# ATSAMR21E/GA register map
Vendor: Atmel Corporation; Series: SAMR21; File version: A
CPU: CM0+ r0p1, little endian, no MPU, no FPU, VTOR, 2 interrupt priority bits
Registers are 8-bit, read-write, reset 0x0 unless marked. A register's access mark holds for its fields unless they carry their own. Offsets are from the block's base; [hi:lo] are bit positions; {n}, {i} and the like mark numbered series; 'fields as' and 'values as' point back to an identical list.

## TCC0 — Timer Counter Control 0
Base 0x42002000; register names take the prefix TCC_
Same registers: TCC1 0x42002400, TCC2 0x42002800
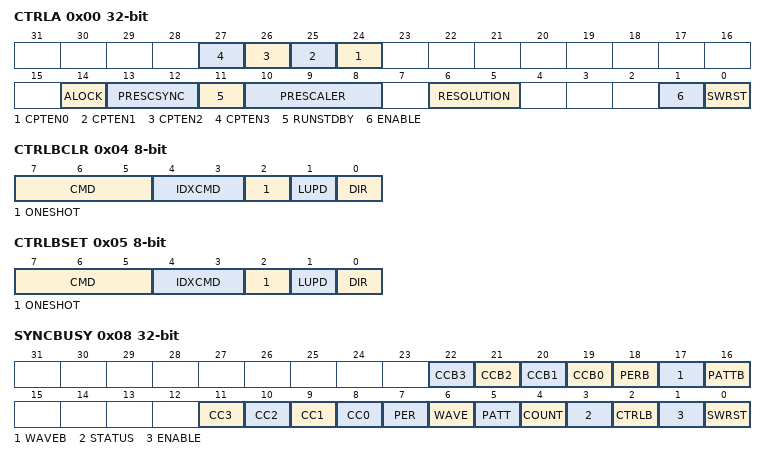
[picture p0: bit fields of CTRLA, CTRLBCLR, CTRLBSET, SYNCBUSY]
0x00 CTRLA 32-bit — Control A
  [n+24] CPTEN{n} (n=0..3) — Capture Channel {n} Enable
  [14] ALOCK — Auto Lock
  [13:12] PRESCSYNC — Prescaler and Counter Synchronization Selection
    0=GCLK (Reload or reset Counter on next GCLK); 1=PRESC (Reload or reset Counter on next prescaler clock); 2=RESYNC (Reload or reset Counter on next GCLK)
  [11] RUNSTDBY — Run in Standby
  [10:8] PRESCALER
    0=DIV1 (Prescaler: GCLK_TCC); 1=DIV2 (Prescaler: GCLK_TCC/2); 2=DIV4 (Prescaler: GCLK_TCC/4); 3=DIV8 (Prescaler: GCLK_TCC/8); 4=DIV16 (Prescaler: GCLK_TCC/16); 5=DIV64 (Prescaler: GCLK_TCC/64); 6=DIV256 (Prescaler: GCLK_TCC/256); 7=DIV1024 (Prescaler: GCLK_TCC/1024)
  [6:5] RESOLUTION — Enhanced Resolution
    0=None (Dithering is disabled); 1=DITH4 (Dithering is done every 16 PWM frames. PER[3:0] and CCx[3:0] contain dithering pattern selection.); 2=DITH5 (Dithering is done every 32 PWM frames. PER[4:0] and CCx[4:0] contain dithering pattern selection.); 3=DITH6 (Dithering is done every 64 PWM frames. PER[5:0] and CCx[5:0] contain dithering pattern selection.)
  [1] ENABLE
  [0] SWRST — Software Reset
0x04 CTRLBCLR — Control B Clear
  [7:5] CMD — TCC Command
    0=NONE (No action); 1=RETRIGGER (Clear start, restart or retrigger); 2=STOP (Force stop); 3=UPDATE (Force update of double buffered registers); 4=READSYNC (Force COUNT read synchronization)
  [4:3] IDXCMD — Ramp Index Command
    0=DISABLE (Command disabled: IDX toggles between cycles A and B); 1=SET (Set IDX: cycle B will be forced in the next cycle); 2=CLEAR (Clear IDX: cycle A will be forced in next cycle); 3=HOLD (Hold IDX: the next cycle will be the same as the current cycle.)
  [2] ONESHOT
  [1] LUPD — Lock Update
  [0] DIR — Counter Direction
0x05 CTRLBSET — Control B Set
  [7:5] CMD — TCC Command
    0=NONE; 1=RETRIGGER; 2=STOP; 3=UPDATE; 4=READSYNC
  [4:3] IDXCMD — Ramp Index Command
    0=DISABLE; 1=SET; 2=CLEAR; 3=HOLD
  [2] ONESHOT
  [1] LUPD — Lock update
  [0] DIR — Counter Direction
0x08 SYNCBUSY 32-bit ro — Synchronization Busy
  [n+19] CCB{n} (n=0..3) — Compare Channel Buffer {n} Busy
  [18] PERB — Period Buffer Busy
  [17] WAVEB — Wave Buffer Busy
  [16] PATTB — Pattern Buffer Busy
  [n+8] CC{n} (n=0..3) — Compare Channel Buffer {n} Busy
  [7] PER — Period busy
  [6] WAVE — Wave Busy
  [5] PATT — Pattern Busy
  [4] COUNT — Count Busy
  [3] STATUS — Status Busy
  [2] CTRLB — Ctrlb Busy
  [1] ENABLE — Enable Busy
  [0] SWRST — Swrst Busy
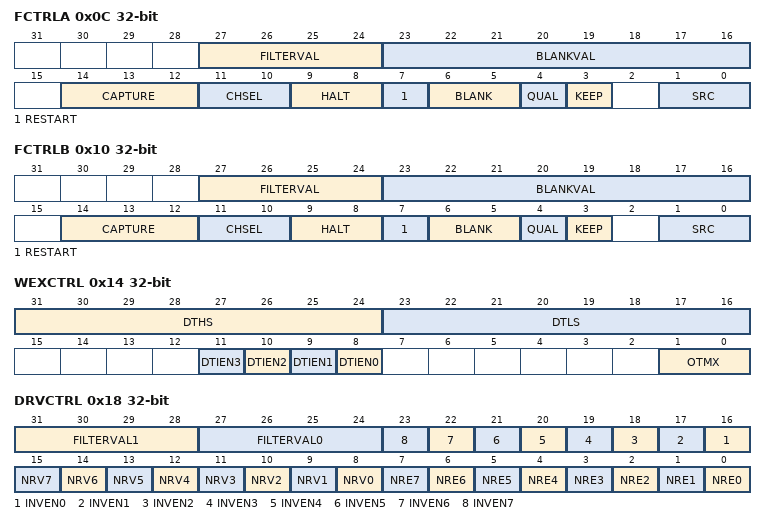
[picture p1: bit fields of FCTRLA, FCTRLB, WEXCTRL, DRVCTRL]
0x0C FCTRLA 32-bit — Recoverable FaultA Configuration
  [27:24] FILTERVAL — FaultA Filter Value
  [23:16] BLANKVAL — FaultA Blanking Time
  [14:12] CAPTURE — FaultA Capture Action
    0=DISABLE; 1=CAPT; 2=CAPTMIN; 3=CAPTMAX; 4=LOCMIN; 5=LOCMAX; 6=DERIV0
  [11:10] CHSEL — FaultA Capture Channel
    {v}=CC{v} (v=0..3)
  [9:8] HALT — FaultA Halt Mode
    0=DISABLE; 1=HW; 2=SW; 3=NR
  [7] RESTART — FaultA Restart
  [6:5] BLANK — FaultA Blanking Mode
    0=DISABLE; 1=RISE; 2=FALL; 3=BOTH
  [4] QUAL — FaultA Qualification
  [3] KEEP — FaultA Keeper
  [1:0] SRC — FaultA Source
    0=DISABLE; 1=ENABLE; 2=INVERT; 3=ALTFAULT
0x10 FCTRLB 32-bit — Recoverable FaultB Configuration
  [27:24] FILTERVAL — FaultB Filter Value
  [23:16] BLANKVAL — FaultB Blanking Time
  [14:12] CAPTURE — FaultB Capture Action
    values as FCTRLA.CAPTURE
  [11:10] CHSEL — FaultB Capture Channel
    {v}=CC{v} (v=0..3)
  [9:8] HALT — FaultB Halt Mode
    0=DISABLE; 1=HW; 2=SW; 3=NR
  [7] RESTART — FaultB Restart
  [6:5] BLANK — FaultB Blanking Mode
    0=DISABLE; 1=RISE; 2=FALL; 3=BOTH
  [4] QUAL — FaultB Qualification
  [3] KEEP — FaultB Keeper
  [1:0] SRC — FaultB Source
    0=DISABLE; 1=ENABLE; 2=INVERT; 3=ALTFAULT
0x14 WEXCTRL 32-bit — Waveform Extension Configuration
  [31:24] DTHS — Dead-time High Side Outputs Value
  [23:16] DTLS — Dead-time Low Side Outputs Value
  [n+8] DTIEN{n} (n=0..3) — Dead-time Insertion Generator {n} Enable
  [1:0] OTMX — Output Matrix
0x18 DRVCTRL 32-bit — Driver Configuration
  [31:28] FILTERVAL1 — Non-Recoverable Fault Input 1 Filter Value
  [27:24] FILTERVAL0 — Non-Recoverable Fault Input 0 Filter Value
  [n+16] INVEN{n} (n=0..7) — Output Waveform {n} Inversion
  [n+8] NRV{n} (n=0..7) — Non-Recoverable State {n} Output Value
  [n] NRE{n} (n=0..7) — Non-Recoverable State {n} Output Enable
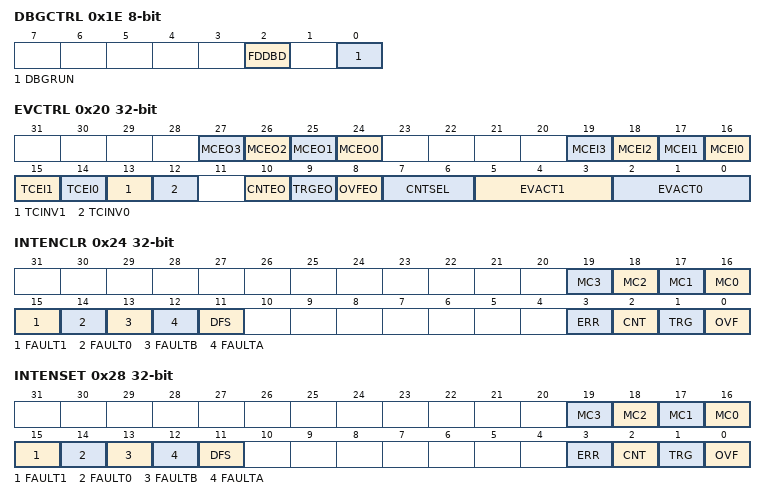
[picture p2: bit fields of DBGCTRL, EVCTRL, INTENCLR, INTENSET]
0x1E DBGCTRL — Debug Control
  [2] FDDBD — Fault Detection on Debug Break Detection
  [0] DBGRUN — Debug Running Mode
0x20 EVCTRL 32-bit — Event Control
  [n+24] MCEO{n} (n=0..3) — Match or Capture Channel {n} Event Output Enable
  [n+16] MCEI{n} (n=0..3) — Match or Capture Channel {n} Event Input Enable
  [15] TCEI1 — Timer/counter Event 1 Input Enable
  [14] TCEI0 — Timer/counter Event 0 Input Enable
  [13] TCINV1 — Inverted Event 1 Input Enable
  [12] TCINV0 — Inverted Event 0 Input Enable
  [10] CNTEO — Timer/counter Output Event Enable
  [9] TRGEO — Retrigger Output Event Enable
  [8] OVFEO — Overflow/Underflow Output Event Enable
  [7:6] CNTSEL — Timer/counter Output Event Mode
    0=START (An interrupt/event is generated when a new counter cycle starts); 1=END (An interrupt/event is generated when a counter cycle ends); 2=BETWEEN (An interrupt/event is generated when a counter cycle ends, except for the first and last cycles.); 3=BOUNDARY (An interrupt/event is generated when a new counter cycle starts or a counter cycle ends)
  [5:3] EVACT1 — Timer/counter Input Event1 Action
    0=OFF (Event action disabled.); 1=RETRIGGER (Re-trigger TC on event); 2=DIR (Direction control); 3=STOP (Stop TC on event); 4=DEC (Decrement TC on event); 5=PPW (Period captured into CC0 Pulse Width on CC1); 6=PWP (Period captured into CC1 Pulse Width on CC0); 7=FAULT (Non-recoverable Fault)
  [2:0] EVACT0 — Timer/counter Input Event0 Action
    0=OFF (Event action disabled.); 1=RETRIGGER (Start restart or re-trigger TC on event); 2=COUNTEV (Count on event. Increment or decrement depending on count direction.); 3=START (Count on event.Start counting on the event rising edge. Further events will not restart the counter; it keeps on counting using prescaled GCLK_TCCx, until it reaches TOP or Zero depending on the direction.); 4=INC (Increment TC on EVENT. Increment the counter on event, irrespective of count direction); 5=COUNT (Count on active state of asynchronous event); 7=FAULT (Non-recoverable Fault)
0x24 INTENCLR 32-bit — Interrupt Enable Clear
  [n+16] MC{n} (n=0..3) — Match or Capture Channel {n} Interrupt Enable
  [15] FAULT1 — Non-Recoverable Fault 1 Interrupt Enable
  [14] FAULT0 — Non-Recoverable Fault 0 Interrupt Enable
  [13] FAULTB — Recoverable FaultB Interrupt Enable
  [12] FAULTA — Recoverable FaultA Interrupt Enable
  [11] DFS — Non-recoverable Debug Fault Interrupt Enable
  [3] ERR — Error Interrupt Enable
  [2] CNT — Counter Interrupt Enable
  [1] TRG — Retrigger Interrupt Enable
  [0] OVF — Overflow Interrupt Enable
0x28 INTENSET 32-bit — Interrupt Enable Set
  [n+16] MC{n} (n=0..3) — Match or Capture Channel {n} Interrupt Enable
  [15] FAULT1 — Non-Recoverable Fault 1 Interrupt Enabl
  [14] FAULT0 — Non-Recoverable Fault 0 Interrupt Enable
  [13] FAULTB — Recoverable FaultB Interrupt Enable
  [12] FAULTA — Recoverable FaultA Interrupt Enable
  [11] DFS — Non-Recoverable Debug Fault Interrupt Enable
  [3] ERR — Error Interrupt Enable
  [2] CNT — Counter Interrupt Enable
  [1] TRG — Retrigger Interrupt Enable
  [0] OVF — Overflow Interrupt Enable
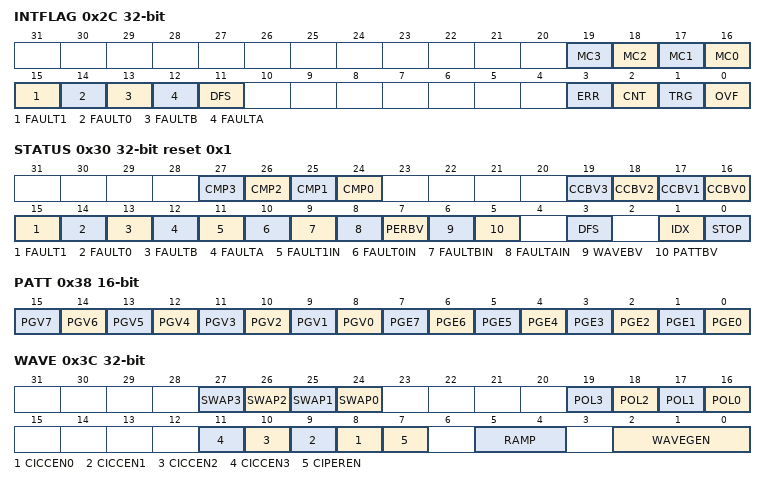
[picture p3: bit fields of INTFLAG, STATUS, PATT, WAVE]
0x2C INTFLAG 32-bit — Interrupt Flag Status and Clear
  [n+16] MC{n} (n=0..3) — Match or Capture {n}
  [15] FAULT1 — Non-Recoverable Fault 1
  [14] FAULT0 — Non-Recoverable Fault 0
  [13] FAULTB — Recoverable FaultB
  [12] FAULTA — Recoverable FaultA
  [11] DFS — Non-Recoverable Debug Fault
  [3] ERR — Error
  [2] CNT — Counter
  [1] TRG — Retrigger
  [0] OVF — Overflow
0x30 STATUS 32-bit reset 0x1
  [n+24] CMP{n} ro (n=0..3) — Compare Channel {n} Value
  [n+16] CCBV{n} (n=0..3) — Compare Channel {n} Buffer Valid
  [15] FAULT1 — Non-Recoverable Fault 1 State
  [14] FAULT0 — Non-Recoverable Fault 0 State
  [13] FAULTB — Recoverable FaultB State
  [12] FAULTA — Recoverable FaultA State
  [11] FAULT1IN ro — Non-Recoverable Fault1 Input
  [10] FAULT0IN ro — Non-Recoverable Fault0 Input
  [9] FAULTBIN ro — Recoverable FaultB Input
  [8] FAULTAIN ro — Recoverable FaultA Input
  [7] PERBV — Period Buffer Valid
  [6] WAVEBV — Wave Buffer Valid
  [5] PATTBV — Pattern Buffer Valid
  [3] DFS — Non-Recoverable Debug Fault State
  [1] IDX ro — Ramp
  [0] STOP ro
0x34 COUNT 32-bit
  [23:0] COUNT — Count Value
0x38 PATT 16-bit — Pattern
  [n+8] PGV{n} (n=0..7) — Pattern Generator {n} Output Value
  [n] PGE{n} (n=0..7) — Pattern Generator {n} Output Enable
0x3C WAVE 32-bit — Waveform Control
  [n+24] SWAP{n} (n=0..3) — Swap DTI Output Pair {n}
  [n+16] POL{n} (n=0..3) — Channel {n} Polarity
  [n+8] CICCEN{n} (n=0..3) — Circular Channel {n} Enable
  [7] CIPEREN — Circular period Enable
  [5:4] RAMP — Ramp Mode
    0=RAMP1; 1=RAMP2A; 2=RAMP2
  [2:0] WAVEGEN — Waveform Generation
    0=NFRQ; 1=MFRQ; 2=NPWM; 4=DSCRITICAL; 5=DSBOTTOM; 6=DSBOTH; 7=DSTOP
0x40 PER 32-bit reset 0xFFFFFFFF — Period
  [23:0] PER — Period Value
{0x44+4i} CC{i} (i=0..3) 32-bit — Compare and Capture
  [23:0] CC — Compare and Capture value
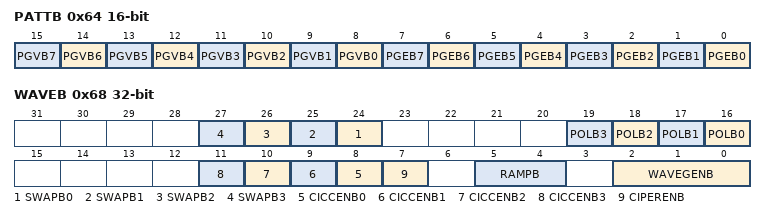
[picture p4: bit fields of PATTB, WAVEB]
0x64 PATTB 16-bit — Pattern Buffer
  [n+8] PGVB{n} (n=0..7) — Pattern Generator {n} Output Enable
  [n] PGEB{n} (n=0..7) — Pattern Generator {n} Output Enable Buffer
0x68 WAVEB 32-bit — Waveform Control Buffer
  [n+24] SWAPB{n} (n=0..3) — Swap DTI Output Pair {n} Buffer
  [n+16] POLB{n} (n=0..3) — Channel {n} Polarity Buffer
  [n+8] CICCENB{n} (n=0..3) — Circular Channel {n} Enable Buffer
  [7] CIPERENB — Circular Period Enable Buffer
  [5:4] RAMPB — Ramp Mode Buffer
  [2:0] WAVEGENB — Waveform Generation Buffer
    values as WAVE.WAVEGEN
0x6C PERB 32-bit reset 0xFFFFFFFF — Period Buffer
  [23:0] PERB — Period Value
{0x70+4i} CCB{i} (i=0..3) 32-bit — Compare and Capture Buffer
  [23:0] CCB — Compare and Capture buffer value

## Notices in the file
Atmel Microcontroller Software Support
Copyright (c) 2014, Atmel Corporation
All rights reserved.
Redistribution and use in source and binary forms, with or without
modification, are permitted provided that the following condition is met:
- Redistributions of source code must retain the above copyright notice,
this list of conditions and the disclaimer below.
Atmel's name may not be used to endorse or promote products derived from
this software without specific prior written permission.
DISCLAIMER: THIS SOFTWARE IS PROVIDED BY ATMEL "AS IS" AND ANY EXPRESS OR
IMPLIED WARRANTIES, INCLUDING, BUT NOT LIMITED TO, THE IMPLIED WARRANTIES OF
MERCHANTABILITY, FITNESS FOR A PARTICULAR PURPOSE AND NON-INFRINGEMENT ARE
DISCLAIMED. IN NO EVENT SHALL ATMEL BE LIABLE FOR ANY DIRECT, INDIRECT,
INCIDENTAL, SPECIAL, EXEMPLARY, OR CONSEQUENTIAL DAMAGES (INCLUDING, BUT NOT
LIMITED TO, PROCUREMENT OF SUBSTITUTE GOODS OR SERVICES; LOSS OF USE, DATA,
OR PROFITS; OR BUSINESS INTERRUPTION) HOWEVER CAUSED AND ON ANY THEORY OF
LIABILITY, WHETHER IN CONTRACT, STRICT LIABILITY, OR TORT (INCLUDING
NEGLIGENCE OR OTHERWISE) ARISING IN ANY WAY OUT OF THE USE OF THIS SOFTWARE,
EVEN IF ADVISED OF THE POSSIBILITY OF SUCH DAMAGE.
